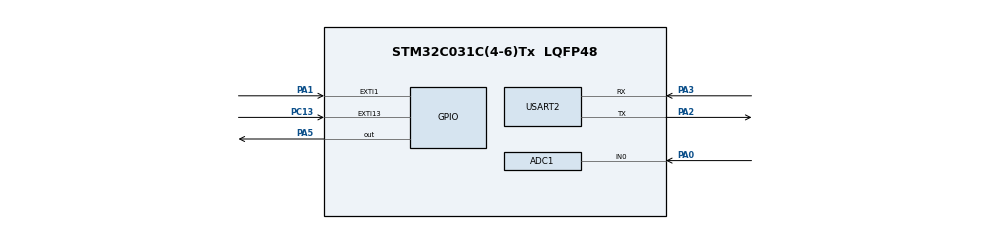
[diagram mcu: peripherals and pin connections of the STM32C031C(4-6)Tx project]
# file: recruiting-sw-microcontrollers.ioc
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ADC1.ContinuousConvMode=DISABLE
ADC1.DMAContinuousRequests=ENABLE
ADC1.ExternalTrigConv=ADC_EXTERNALTRIG_T3_TRGO
ADC1.NbrOfConversionFlag=0
ADC1.SamplingTimeCommon1=ADC_SAMPLETIME_160CYCLES_5
ADC1.SelectedChannel=ADC_CHANNEL_0
ADC1.master=1
Dma.ADC1.1.Direction=DMA_PERIPH_TO_MEMORY
Dma.ADC1.1.EventEnable=DISABLE
Dma.ADC1.1.Instance=DMA1_Channel2
Dma.ADC1.1.MemDataAlignment=DMA_MDATAALIGN_HALFWORD
Dma.ADC1.1.MemInc=DMA_MINC_ENABLE
Dma.ADC1.1.Mode=DMA_CIRCULAR
Dma.ADC1.1.PeriphDataAlignment=DMA_PDATAALIGN_HALFWORD
Dma.ADC1.1.PeriphInc=DMA_PINC_DISABLE
Dma.ADC1.1.Polarity=HAL_DMAMUX_REQ_GEN_RISING
Dma.ADC1.1.Priority=DMA_PRIORITY_LOW
Dma.ADC1.1.RequestNumber=1
Dma.ADC1.1.SignalID=NONE
Dma.ADC1.1.SyncEnable=DISABLE
Dma.ADC1.1.SyncPolarity=HAL_DMAMUX_SYNC_NO_EVENT
Dma.ADC1.1.SyncRequestNumber=1
Dma.ADC1.1.SyncSignalID=NONE
Dma.Request0=USART2_TX
Dma.Request1=ADC1
Dma.USART2_TX.0.Direction=DMA_MEMORY_TO_PERIPH
Dma.USART2_TX.0.EventEnable=DISABLE
Dma.USART2_TX.0.Instance=DMA1_Channel1
Dma.USART2_TX.0.MemDataAlignment=DMA_MDATAALIGN_BYTE
Dma.USART2_TX.0.MemInc=DMA_MINC_ENABLE
Dma.USART2_TX.0.Mode=DMA_NORMAL
Dma.USART2_TX.0.PeriphDataAlignment=DMA_PDATAALIGN_BYTE
Dma.USART2_TX.0.PeriphInc=DMA_PINC_DISABLE
Dma.USART2_TX.0.Polarity=HAL_DMAMUX_REQ_GEN_RISING
Dma.USART2_TX.0.Priority=DMA_PRIORITY_LOW
Dma.USART2_TX.0.RequestNumber=1
Dma.USART2_TX.0.SignalID=NONE
Dma.USART2_TX.0.SyncEnable=DISABLE
Dma.USART2_TX.0.SyncPolarity=HAL_DMAMUX_SYNC_NO_EVENT
Dma.USART2_TX.0.SyncRequestNumber=1
Dma.USART2_TX.0.SyncSignalID=NONE
Mcu.Family=STM32C0
Mcu.Name=STM32C031C(4-6)Tx
Mcu.Package=LQFP48
NVIC.DMA1_Channel1_IRQn=true\:0\:0\:false\:false\:true\:false\:true\:true
NVIC.DMA1_Channel2_3_IRQn=true\:0\:0\:false\:false\:true\:false\:true\:true
NVIC.EXTI0_1_IRQn=true\:0\:0\:false\:false\:true\:true\:true\:true
NVIC.EXTI4_15_IRQn=true\:0\:0\:false\:false\:true\:true\:true\:true
NVIC.TIM14_IRQn=true\:0\:0\:false\:false\:true\:true\:true\:true
NVIC.TIM16_IRQn=true\:0\:0\:false\:false\:true\:true\:true\:true
NVIC.TIM1_BRK_UP_TRG_COM_IRQn=true\:0\:0\:false\:false\:true\:true\:true\:true
NVIC.USART2_IRQn=true\:0\:0\:false\:false\:true\:true\:true\:true
PA0.Mode=IN0
PA0.Signal=ADC1_IN0
PA1.GPIO_ModeDefaultEXTI=GPIO_MODE_IT_RISING_FALLING
PA1.GPIO_PuPd=GPIO_PULLDOWN
PA1.Signal=GPXTI1
PA2.Mode=Asynchronous
PA2.Signal=USART2_TX
PA3.Mode=Asynchronous
PA3.Signal=USART2_RX
PA5.Signal=GPIO_Output
PC13.GPIO_ModeDefaultEXTI=GPIO_MODE_IT_FALLING
PC13.GPIO_PuPd=GPIO_PULLDOWN
PC13.Signal=GPXTI13
ProjectManager.HeapSize=0x200
ProjectManager.StackSize=0x400
ProjectManager.TargetToolchain=Makefile
RCC.ADCFreq_Value=12000000
RCC.AHBFreq_Value=12000000
RCC.CortexFreq_Value=12000000
RCC.EXTERNAL_CLOCK_VALUE=12288000
RCC.HCLKFreq_Value=12000000
RCC.HSE_VALUE=8000000
RCC.HSI_VALUE=48000000
RCC.LSE_VALUE=32768
RCC.SYSCLKFreq_VALUE=12000000
TIM1.Period=4999
TIM1.Prescaler=11999
TIM14.Period=999
TIM14.Prescaler=11999
TIM16.Period=199
TIM16.Prescaler=11999
TIM3.Period=9
TIM3.Prescaler=1199
TIM3.TIM_MasterOutputTrigger=TIM_TRGO_UPDATE
USART2.VirtualMode-Asynchronous=VM_ASYNC
VP_TIM14_VS_ClockSourceINT.Mode=Enable_Timer
VP_TIM16_VS_ClockSourceINT.Mode=Enable_Timer
VP_TIM1_VS_ClockSourceINT.Mode=Internal
VP_TIM1_VS_OPM.Mode=OPM_bit
VP_TIM3_VS_ClockSourceINT.Mode=Internal
board=custom

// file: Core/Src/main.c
/* USER CODE BEGIN Header */
/**
 ******************************************************************************
 * @file           : main.c
 * @brief          : Main program body
 ******************************************************************************
 * @attention
 *
 * Copyright (c) 2026 STMicroelectronics.
 * All rights reserved.
 *
 * This software is licensed under terms that can be found in the LICENSE file
 * in the root directory of this software component.
 * If no LICENSE file comes with this software, it is provided AS-IS.
 *
 ******************************************************************************
 */
/* USER CODE END Header */
#include "main.h"

/* USER CODE BEGIN Includes */

#include "fsm.h"
#include "fsm_types.h"
#include "queue_event.h"

/* USER CODE END Includes */

ADC_HandleTypeDef hadc1;
DMA_HandleTypeDef hdma_adc1;

TIM_HandleTypeDef htim1;
TIM_HandleTypeDef htim3;
TIM_HandleTypeDef htim14;
TIM_HandleTypeDef htim16;

UART_HandleTypeDef huart2;
DMA_HandleTypeDef hdma_usart2_tx;

void SystemClock_Config(void);
static void MX_GPIO_Init(void);
static void MX_DMA_Init(void);
static void MX_USART2_UART_Init(void);
static void MX_ADC1_Init(void);
static void MX_TIM1_Init(void);
static void MX_TIM3_Init(void);
static void MX_TIM14_Init(void);
static void MX_TIM16_Init(void);

int main(void) {

   /* MCU
    * Configuration--------------------------------------------------------*/

   /* Reset of all peripherals, Initializes the Flash interface and the Systick.
    */
   HAL_Init();

   /* Configure the system clock */
   SystemClock_Config();

   /* Initialize all configured peripherals */
   MX_GPIO_Init();
   MX_DMA_Init();
   MX_USART2_UART_Init();
   MX_ADC1_Init();
   MX_TIM1_Init();
   MX_TIM3_Init();
   MX_TIM14_Init();
   MX_TIM16_Init();
   /* USER CODE BEGIN 2 */

   curr_state = STATE_INIT;

   /* USER CODE END 2 */

   /* Infinite loop */
   while (1) {

      /* USER CODE BEGIN 3 */

      fsm_dispatch();
   }
   /* USER CODE END 3 */
}

void SystemClock_Config(void) {
   RCC_OscInitTypeDef RCC_OscInitStruct = {0};
   RCC_ClkInitTypeDef RCC_ClkInitStruct = {0};

   __HAL_FLASH_SET_LATENCY(FLASH_LATENCY_0);

   /** Initializes the RCC Oscillators according to the specified parameters
    * in the RCC_OscInitTypeDef structure.
    */
   RCC_OscInitStruct.OscillatorType = RCC_OSCILLATORTYPE_HSI;
   RCC_OscInitStruct.HSIState = RCC_HSI_ON;
   RCC_OscInitStruct.HSIDiv = RCC_HSI_DIV4;
   RCC_OscInitStruct.HSICalibrationValue = RCC_HSICALIBRATION_DEFAULT;
   if (HAL_RCC_OscConfig(&RCC_OscInitStruct) != HAL_OK) {
      Error_Handler();
   }

   /** Initializes the CPU, AHB and APB buses clocks
    */
   RCC_ClkInitStruct.ClockType =
       RCC_CLOCKTYPE_HCLK | RCC_CLOCKTYPE_SYSCLK | RCC_CLOCKTYPE_PCLK1;
   RCC_ClkInitStruct.SYSCLKSource = RCC_SYSCLKSOURCE_HSI;
   RCC_ClkInitStruct.SYSCLKDivider = RCC_SYSCLK_DIV1;
   RCC_ClkInitStruct.AHBCLKDivider = RCC_HCLK_DIV1;
   RCC_ClkInitStruct.APB1CLKDivider = RCC_APB1_DIV1;

   if (HAL_RCC_ClockConfig(&RCC_ClkInitStruct, FLASH_LATENCY_0) != HAL_OK) {
      Error_Handler();
   }
}

static void MX_ADC1_Init(void) {

   ADC_ChannelConfTypeDef sConfig = {0};

   /** Configure the global features of the ADC (Clock, Resolution, Data
    * Alignment and number of conversion)
    */
   hadc1.Instance = ADC1;
   hadc1.Init.ClockPrescaler = ADC_CLOCK_SYNC_PCLK_DIV1;
   hadc1.Init.Resolution = ADC_RESOLUTION_12B;
   hadc1.Init.DataAlign = ADC_DATAALIGN_RIGHT;
   hadc1.Init.ScanConvMode = ADC_SCAN_SEQ_FIXED;
   hadc1.Init.EOCSelection = ADC_EOC_SINGLE_CONV;
   hadc1.Init.LowPowerAutoWait = DISABLE;
   hadc1.Init.LowPowerAutoPowerOff = DISABLE;
   hadc1.Init.ContinuousConvMode = DISABLE;
   hadc1.Init.NbrOfConversion = 1;
   hadc1.Init.DiscontinuousConvMode = DISABLE;
   hadc1.Init.ExternalTrigConv = ADC_EXTERNALTRIG_T3_TRGO;
   hadc1.Init.ExternalTrigConvEdge = ADC_EXTERNALTRIGCONVEDGE_RISING;
   hadc1.Init.DMAContinuousRequests = ENABLE;
   hadc1.Init.Overrun = ADC_OVR_DATA_PRESERVED;
   hadc1.Init.SamplingTimeCommon1 = ADC_SAMPLETIME_160CYCLES_5;
   hadc1.Init.OversamplingMode = DISABLE;
   hadc1.Init.TriggerFrequencyMode = ADC_TRIGGER_FREQ_HIGH;
   if (HAL_ADC_Init(&hadc1) != HAL_OK) {
      Error_Handler();
   }

   /** Configure Regular Channel
    */
   sConfig.Channel = ADC_CHANNEL_0;
   sConfig.Rank = ADC_RANK_CHANNEL_NUMBER;
   if (HAL_ADC_ConfigChannel(&hadc1, &sConfig) != HAL_OK) {
      Error_Handler();
   }
}

static void MX_TIM1_Init(void) {

   TIM_ClockConfigTypeDef sClockSourceConfig = {0};
   TIM_MasterConfigTypeDef sMasterConfig = {0};

   htim1.Instance = TIM1;
   htim1.Init.Prescaler = 11999;
   htim1.Init.CounterMode = TIM_COUNTERMODE_UP;
   htim1.Init.Period = 4999;
   htim1.Init.ClockDivision = TIM_CLOCKDIVISION_DIV1;
   htim1.Init.RepetitionCounter = 0;
   htim1.Init.AutoReloadPreload = TIM_AUTORELOAD_PRELOAD_DISABLE;
   if (HAL_TIM_Base_Init(&htim1) != HAL_OK) {
      Error_Handler();
   }
   sClockSourceConfig.ClockSource = TIM_CLOCKSOURCE_INTERNAL;
   if (HAL_TIM_ConfigClockSource(&htim1, &sClockSourceConfig) != HAL_OK) {
      Error_Handler();
   }
   if (HAL_TIM_OnePulse_Init(&htim1, TIM_OPMODE_SINGLE) != HAL_OK) {
      Error_Handler();
   }
   sMasterConfig.MasterOutputTrigger = TIM_TRGO_RESET;
   sMasterConfig.MasterOutputTrigger2 = TIM_TRGO2_RESET;
   sMasterConfig.MasterSlaveMode = TIM_MASTERSLAVEMODE_DISABLE;
   if (HAL_TIMEx_MasterConfigSynchronization(&htim1, &sMasterConfig) !=
       HAL_OK) {
      Error_Handler();
   }
}

static void MX_TIM3_Init(void) {

   TIM_ClockConfigTypeDef sClockSourceConfig = {0};
   TIM_MasterConfigTypeDef sMasterConfig = {0};

   htim3.Instance = TIM3;
   htim3.Init.Prescaler = 1199;
   htim3.Init.CounterMode = TIM_COUNTERMODE_UP;
   htim3.Init.Period = 9;
   htim3.Init.ClockDivision = TIM_CLOCKDIVISION_DIV1;
   htim3.Init.AutoReloadPreload = TIM_AUTORELOAD_PRELOAD_DISABLE;
   if (HAL_TIM_Base_Init(&htim3) != HAL_OK) {
      Error_Handler();
   }
   sClockSourceConfig.ClockSource = TIM_CLOCKSOURCE_INTERNAL;
   if (HAL_TIM_ConfigClockSource(&htim3, &sClockSourceConfig) != HAL_OK) {
      Error_Handler();
   }
   sMasterConfig.MasterOutputTrigger = TIM_TRGO_UPDATE;
   sMasterConfig.MasterSlaveMode = TIM_MASTERSLAVEMODE_DISABLE;
   if (HAL_TIMEx_MasterConfigSynchronization(&htim3, &sMasterConfig) !=
       HAL_OK) {
      Error_Handler();
   }
}

static void MX_TIM14_Init(void) {

   htim14.Instance = TIM14;
   htim14.Init.Prescaler = 11999;
   htim14.Init.CounterMode = TIM_COUNTERMODE_UP;
   htim14.Init.Period = 999;
   htim14.Init.ClockDivision = TIM_CLOCKDIVISION_DIV1;
   htim14.Init.AutoReloadPreload = TIM_AUTORELOAD_PRELOAD_DISABLE;
   if (HAL_TIM_Base_Init(&htim14) != HAL_OK) {
      Error_Handler();
   }
}

static void MX_TIM16_Init(void) {

   htim16.Instance = TIM16;
   htim16.Init.Prescaler = 11999;
   htim16.Init.CounterMode = TIM_COUNTERMODE_UP;
   htim16.Init.Period = 199;
   htim16.Init.ClockDivision = TIM_CLOCKDIVISION_DIV1;
   htim16.Init.RepetitionCounter = 0;
   htim16.Init.AutoReloadPreload = TIM_AUTORELOAD_PRELOAD_DISABLE;
   if (HAL_TIM_Base_Init(&htim16) != HAL_OK) {
      Error_Handler();
   }
}

static void MX_USART2_UART_Init(void) {

   huart2.Instance = USART2;
   huart2.Init.BaudRate = 115200;
   huart2.Init.WordLength = UART_WORDLENGTH_8B;
   huart2.Init.StopBits = UART_STOPBITS_1;
   huart2.Init.Parity = UART_PARITY_NONE;
   huart2.Init.Mode = UART_MODE_TX_RX;
   huart2.Init.HwFlowCtl = UART_HWCONTROL_NONE;
   huart2.Init.OverSampling = UART_OVERSAMPLING_16;
   huart2.Init.OneBitSampling = UART_ONE_BIT_SAMPLE_DISABLE;
   huart2.Init.ClockPrescaler = UART_PRESCALER_DIV1;
   huart2.AdvancedInit.AdvFeatureInit = UART_ADVFEATURE_NO_INIT;
   if (HAL_UART_Init(&huart2) != HAL_OK) {
      Error_Handler();
   }
}

static void MX_DMA_Init(void) {

   /* DMA controller clock enable */
   __HAL_RCC_DMA1_CLK_ENABLE();

   /* DMA interrupt init */
   /* DMA1_Channel1_IRQn interrupt configuration */
   HAL_NVIC_SetPriority(DMA1_Channel1_IRQn, 0, 0);
   HAL_NVIC_EnableIRQ(DMA1_Channel1_IRQn);
   /* DMA1_Channel2_3_IRQn interrupt configuration */
   HAL_NVIC_SetPriority(DMA1_Channel2_3_IRQn, 0, 0);
   HAL_NVIC_EnableIRQ(DMA1_Channel2_3_IRQn);
}

static void MX_GPIO_Init(void) {
   GPIO_InitTypeDef GPIO_InitStruct = {0};

   /* GPIO Ports Clock Enable */
   __HAL_RCC_GPIOC_CLK_ENABLE();
   __HAL_RCC_GPIOA_CLK_ENABLE();

   /*Configure GPIO pin Output Level */
   HAL_GPIO_WritePin(GPIOA, GPIO_PIN_5, GPIO_PIN_RESET);

   /*Configure GPIO pin : PC13 */
   GPIO_InitStruct.Pin = GPIO_PIN_13;
   GPIO_InitStruct.Mode = GPIO_MODE_IT_FALLING;
   GPIO_InitStruct.Pull = GPIO_PULLDOWN;
   HAL_GPIO_Init(GPIOC, &GPIO_InitStruct);

   /*Configure GPIO pin : PA1 */
   GPIO_InitStruct.Pin = GPIO_PIN_1;
   GPIO_InitStruct.Mode = GPIO_MODE_IT_RISING_FALLING;
   GPIO_InitStruct.Pull = GPIO_PULLDOWN;
   HAL_GPIO_Init(GPIOA, &GPIO_InitStruct);

   /*Configure GPIO pin : PA5 */
   GPIO_InitStruct.Pin = GPIO_PIN_5;
   GPIO_InitStruct.Mode = GPIO_MODE_OUTPUT_PP;
   GPIO_InitStruct.Pull = GPIO_NOPULL;
   GPIO_InitStruct.Speed = GPIO_SPEED_FREQ_LOW;
   HAL_GPIO_Init(GPIOA, &GPIO_InitStruct);

   /* EXTI interrupt init*/
   HAL_NVIC_SetPriority(EXTI0_1_IRQn, 0, 0);
   HAL_NVIC_EnableIRQ(EXTI0_1_IRQn);

   HAL_NVIC_SetPriority(EXTI4_15_IRQn, 0, 0);
   HAL_NVIC_EnableIRQ(EXTI4_15_IRQn);

   /* USER CODE BEGIN MX_GPIO_Init_2 */

   HAL_NVIC_SetPriority(EXTI0_1_IRQn, 0, 0);
   HAL_NVIC_EnableIRQ(EXTI0_1_IRQn);

   /* USER CODE END MX_GPIO_Init_2 */
}

void Error_Handler(void) {
   /* USER CODE BEGIN Error_Handler_Debug */
   /* User can add his own implementation to report the HAL error return state
    */
   /*
   __disable_irq();
   while (1)
   {
   }
   */

   queue_clean();
   enqueue_event(EVENT_INVALID);

   /* USER CODE END Error_Handler_Debug */
}
#ifdef USE_FULL_ASSERT
/**
 * @brief  Reports the name of the source file and the source line number
 *         where the assert_param error has occurred.
 * @param  file: pointer to the source file name
 * @param  line: assert_param error line source number
 * @retval None
 */
void assert_failed(uint8_t *file, uint32_t line) {
   /* USER CODE BEGIN 6 */
   /* User can add his own implementation to report the file name and line
      number, ex: printf("Wrong parameters value: file %s on line %d\r\n", file,
      line) */
   /* USER CODE END 6 */
}
#endif /* USE_FULL_ASSERT */
